VERSION ""

NS_ :

BS_:

BU_: ALLOCATOR ALLOCATEE

BO_ 1823 node_id_discover: 1 ALLOCATOR
 SG_ session_id : 0|8@1+ (1,0) [0|255] ""  ALLOCATEE

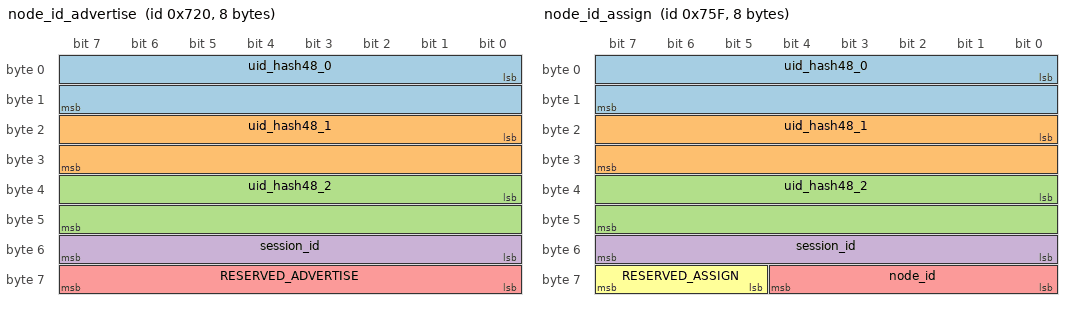
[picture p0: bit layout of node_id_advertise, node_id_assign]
BO_ 1824 node_id_advertise: 8 ALLOCATEE
 SG_ uid_hash48_0 : 0|16@1+ (1,0) [0|65535] "hash48_0"  ALLOCATOR
 SG_ uid_hash48_1 : 16|16@1+ (1,0) [0|65535] "hash48_1"  ALLOCATOR
 SG_ uid_hash48_2 : 32|16@1+ (1,0) [0|65535] "hash48_2"  ALLOCATOR
 SG_ session_id : 48|8@1+ (1,0) [0|255] "session_id"  ALLOCATOR
 SG_ RESERVED_ADVERTISE : 56|8@1+ (1,0) [0|255] ""  ALLOCATOR

BO_ 1887 node_id_assign: 8 ALLOCATOR
 SG_ uid_hash48_0 : 0|16@1+ (1,0) [0|65535] "hash48_0"  ALLOCATEE
 SG_ uid_hash48_1 : 16|16@1+ (1,0) [0|65535] "hash48_1"  ALLOCATEE
 SG_ uid_hash48_2 : 32|16@1+ (1,0) [0|65535] "hash48_2"  ALLOCATEE
 SG_ session_id : 48|8@1+ (1,0) [0|255] "session_id"  ALLOCATEE
 SG_ node_id : 56|5@1+ (1,0) [0|31] "node_id"  ALLOCATEE
 SG_ RESERVED_ASSIGN : 61|3@1+ (1,0) [0|7] ""  ALLOCATEE

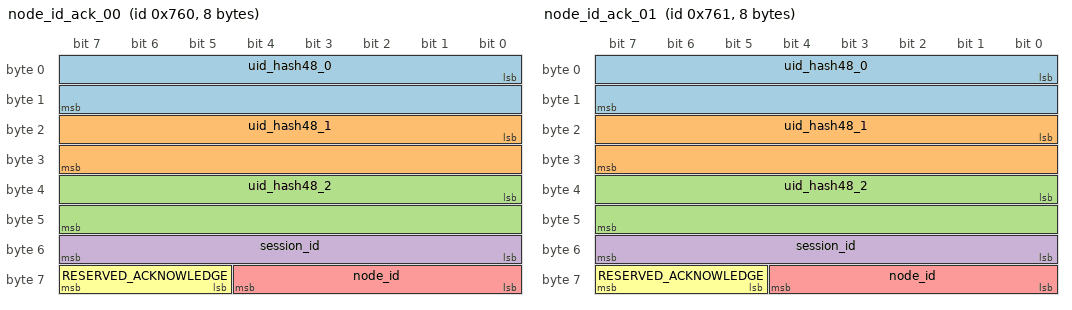
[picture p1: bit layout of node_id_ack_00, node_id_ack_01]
BO_ 1888 node_id_ack_00: 8 ALLOCATEE
 SG_ uid_hash48_0 : 0|16@1+ (1,0) [0|65535] "hash48_0"  ALLOCATOR
 SG_ uid_hash48_1 : 16|16@1+ (1,0) [0|65535] "hash48_1"  ALLOCATOR
 SG_ uid_hash48_2 : 32|16@1+ (1,0) [0|65535] "hash48_2"  ALLOCATOR
 SG_ session_id : 48|8@1+ (1,0) [0|255] "session_id"  ALLOCATOR
 SG_ node_id : 56|5@1+ (1,0) [0|31] "node_id"  ALLOCATOR
 SG_ RESERVED_ACKNOWLEDGE : 61|3@1+ (1,0) [0|7] ""  ALLOCATOR

BO_ 1889 node_id_ack_01: 8 ALLOCATEE
 SG_ uid_hash48_0 : 0|16@1+ (1,0) [0|65535] "hash48_0"  ALLOCATOR
 SG_ uid_hash48_1 : 16|16@1+ (1,0) [0|65535] "hash48_1"  ALLOCATOR
 SG_ uid_hash48_2 : 32|16@1+ (1,0) [0|65535] "hash48_2"  ALLOCATOR
 SG_ session_id : 48|8@1+ (1,0) [0|255] "session_id"  ALLOCATOR
 SG_ node_id : 56|5@1+ (1,0) [0|31] "node_id"  ALLOCATOR
 SG_ RESERVED_ACKNOWLEDGE : 61|3@1+ (1,0) [0|7] ""  ALLOCATOR

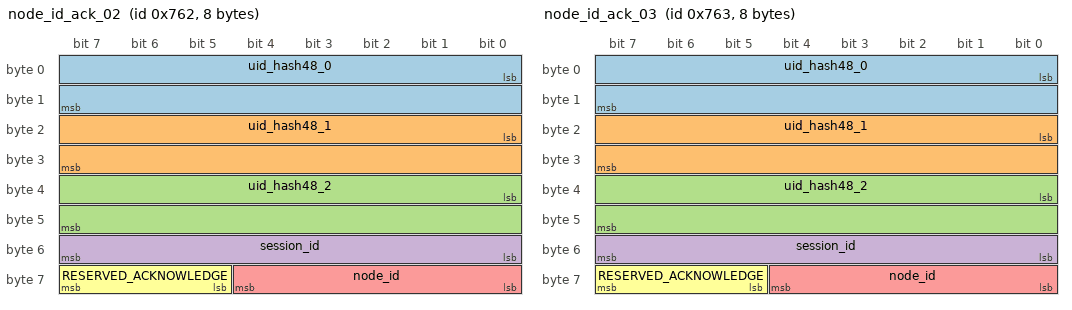
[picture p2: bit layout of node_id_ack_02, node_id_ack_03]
BO_ 1890 node_id_ack_02: 8 ALLOCATEE
 SG_ uid_hash48_0 : 0|16@1+ (1,0) [0|65535] "hash48_0"  ALLOCATOR
 SG_ uid_hash48_1 : 16|16@1+ (1,0) [0|65535] "hash48_1"  ALLOCATOR
 SG_ uid_hash48_2 : 32|16@1+ (1,0) [0|65535] "hash48_2"  ALLOCATOR
 SG_ session_id : 48|8@1+ (1,0) [0|255] "session_id"  ALLOCATOR
 SG_ node_id : 56|5@1+ (1,0) [0|31] "node_id"  ALLOCATOR
 SG_ RESERVED_ACKNOWLEDGE : 61|3@1+ (1,0) [0|7] ""  ALLOCATOR

BO_ 1891 node_id_ack_03: 8 ALLOCATEE
 SG_ uid_hash48_0 : 0|16@1+ (1,0) [0|65535] "hash48_0"  ALLOCATOR
 SG_ uid_hash48_1 : 16|16@1+ (1,0) [0|65535] "hash48_1"  ALLOCATOR
 SG_ uid_hash48_2 : 32|16@1+ (1,0) [0|65535] "hash48_2"  ALLOCATOR
 SG_ session_id : 48|8@1+ (1,0) [0|255] "session_id"  ALLOCATOR
 SG_ node_id : 56|5@1+ (1,0) [0|31] "node_id"  ALLOCATOR
 SG_ RESERVED_ACKNOWLEDGE : 61|3@1+ (1,0) [0|7] ""  ALLOCATOR

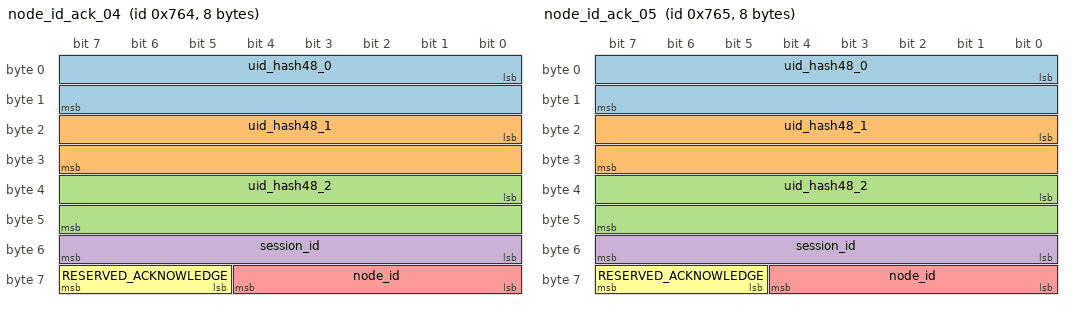
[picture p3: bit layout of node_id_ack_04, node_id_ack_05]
BO_ 1892 node_id_ack_04: 8 ALLOCATEE
 SG_ uid_hash48_0 : 0|16@1+ (1,0) [0|65535] "hash48_0"  ALLOCATOR
 SG_ uid_hash48_1 : 16|16@1+ (1,0) [0|65535] "hash48_1"  ALLOCATOR
 SG_ uid_hash48_2 : 32|16@1+ (1,0) [0|65535] "hash48_2"  ALLOCATOR
 SG_ session_id : 48|8@1+ (1,0) [0|255] "session_id"  ALLOCATOR
 SG_ node_id : 56|5@1+ (1,0) [0|31] "node_id"  ALLOCATOR
 SG_ RESERVED_ACKNOWLEDGE : 61|3@1+ (1,0) [0|7] ""  ALLOCATOR

BO_ 1893 node_id_ack_05: 8 ALLOCATEE
 SG_ uid_hash48_0 : 0|16@1+ (1,0) [0|65535] "hash48_0"  ALLOCATOR
 SG_ uid_hash48_1 : 16|16@1+ (1,0) [0|65535] "hash48_1"  ALLOCATOR
 SG_ uid_hash48_2 : 32|16@1+ (1,0) [0|65535] "hash48_2"  ALLOCATOR
 SG_ session_id : 48|8@1+ (1,0) [0|255] "session_id"  ALLOCATOR
 SG_ node_id : 56|5@1+ (1,0) [0|31] "node_id"  ALLOCATOR
 SG_ RESERVED_ACKNOWLEDGE : 61|3@1+ (1,0) [0|7] ""  ALLOCATOR

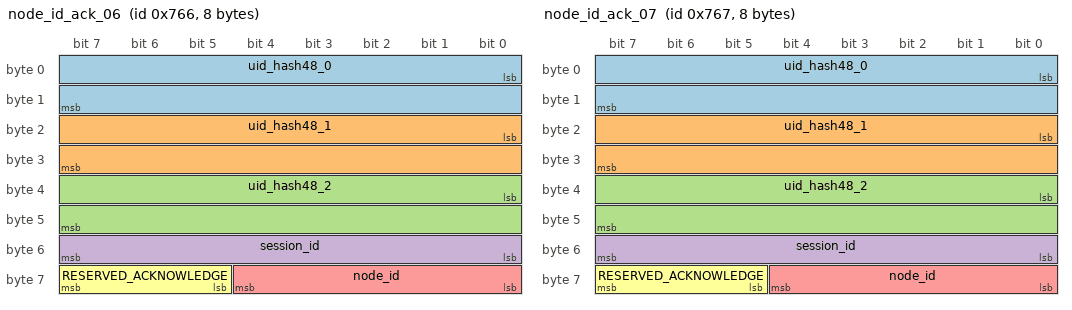
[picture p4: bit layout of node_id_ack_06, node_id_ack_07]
BO_ 1894 node_id_ack_06: 8 ALLOCATEE
 SG_ uid_hash48_0 : 0|16@1+ (1,0) [0|65535] "hash48_0"  ALLOCATOR
 SG_ uid_hash48_1 : 16|16@1+ (1,0) [0|65535] "hash48_1"  ALLOCATOR
 SG_ uid_hash48_2 : 32|16@1+ (1,0) [0|65535] "hash48_2"  ALLOCATOR
 SG_ session_id : 48|8@1+ (1,0) [0|255] "session_id"  ALLOCATOR
 SG_ node_id : 56|5@1+ (1,0) [0|31] "node_id"  ALLOCATOR
 SG_ RESERVED_ACKNOWLEDGE : 61|3@1+ (1,0) [0|7] ""  ALLOCATOR

BO_ 1895 node_id_ack_07: 8 ALLOCATEE
 SG_ uid_hash48_0 : 0|16@1+ (1,0) [0|65535] "hash48_0"  ALLOCATOR
 SG_ uid_hash48_1 : 16|16@1+ (1,0) [0|65535] "hash48_1"  ALLOCATOR
 SG_ uid_hash48_2 : 32|16@1+ (1,0) [0|65535] "hash48_2"  ALLOCATOR
 SG_ session_id : 48|8@1+ (1,0) [0|255] "session_id"  ALLOCATOR
 SG_ node_id : 56|5@1+ (1,0) [0|31] "node_id"  ALLOCATOR
 SG_ RESERVED_ACKNOWLEDGE : 61|3@1+ (1,0) [0|7] ""  ALLOCATOR

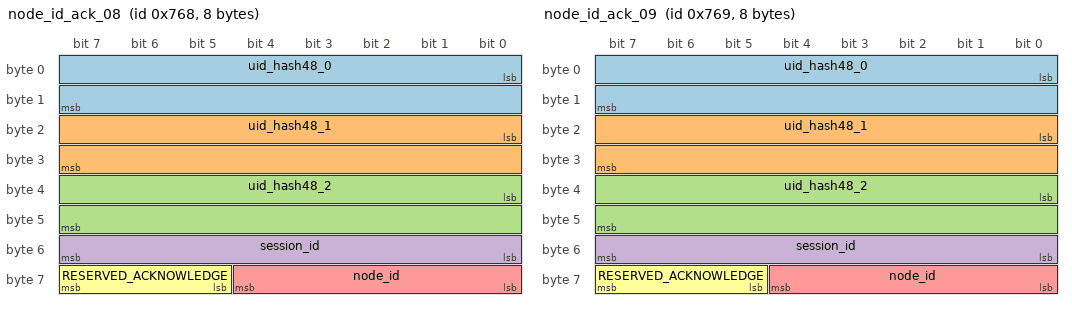
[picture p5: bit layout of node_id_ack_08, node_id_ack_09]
BO_ 1896 node_id_ack_08: 8 ALLOCATEE
 SG_ uid_hash48_0 : 0|16@1+ (1,0) [0|65535] "hash48_0"  ALLOCATOR
 SG_ uid_hash48_1 : 16|16@1+ (1,0) [0|65535] "hash48_1"  ALLOCATOR
 SG_ uid_hash48_2 : 32|16@1+ (1,0) [0|65535] "hash48_2"  ALLOCATOR
 SG_ session_id : 48|8@1+ (1,0) [0|255] "session_id"  ALLOCATOR
 SG_ node_id : 56|5@1+ (1,0) [0|31] "node_id"  ALLOCATOR
 SG_ RESERVED_ACKNOWLEDGE : 61|3@1+ (1,0) [0|7] ""  ALLOCATOR

BO_ 1897 node_id_ack_09: 8 ALLOCATEE
 SG_ uid_hash48_0 : 0|16@1+ (1,0) [0|65535] "hash48_0"  ALLOCATOR
 SG_ uid_hash48_1 : 16|16@1+ (1,0) [0|65535] "hash48_1"  ALLOCATOR
 SG_ uid_hash48_2 : 32|16@1+ (1,0) [0|65535] "hash48_2"  ALLOCATOR
 SG_ session_id : 48|8@1+ (1,0) [0|255] "session_id"  ALLOCATOR
 SG_ node_id : 56|5@1+ (1,0) [0|31] "node_id"  ALLOCATOR
 SG_ RESERVED_ACKNOWLEDGE : 61|3@1+ (1,0) [0|7] ""  ALLOCATOR

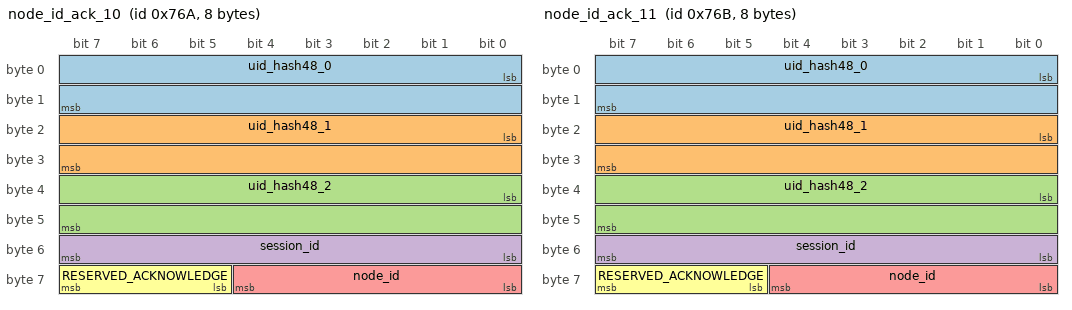
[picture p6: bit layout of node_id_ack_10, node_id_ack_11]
BO_ 1898 node_id_ack_10: 8 ALLOCATEE
 SG_ uid_hash48_0 : 0|16@1+ (1,0) [0|65535] "hash48_0"  ALLOCATOR
 SG_ uid_hash48_1 : 16|16@1+ (1,0) [0|65535] "hash48_1"  ALLOCATOR
 SG_ uid_hash48_2 : 32|16@1+ (1,0) [0|65535] "hash48_2"  ALLOCATOR
 SG_ session_id : 48|8@1+ (1,0) [0|255] "session_id"  ALLOCATOR
 SG_ node_id : 56|5@1+ (1,0) [0|31] "node_id"  ALLOCATOR
 SG_ RESERVED_ACKNOWLEDGE : 61|3@1+ (1,0) [0|7] ""  ALLOCATOR

BO_ 1899 node_id_ack_11: 8 ALLOCATEE
 SG_ uid_hash48_0 : 0|16@1+ (1,0) [0|65535] "hash48_0"  ALLOCATOR
 SG_ uid_hash48_1 : 16|16@1+ (1,0) [0|65535] "hash48_1"  ALLOCATOR
 SG_ uid_hash48_2 : 32|16@1+ (1,0) [0|65535] "hash48_2"  ALLOCATOR
 SG_ session_id : 48|8@1+ (1,0) [0|255] "session_id"  ALLOCATOR
 SG_ node_id : 56|5@1+ (1,0) [0|31] "node_id"  ALLOCATOR
 SG_ RESERVED_ACKNOWLEDGE : 61|3@1+ (1,0) [0|7] ""  ALLOCATOR

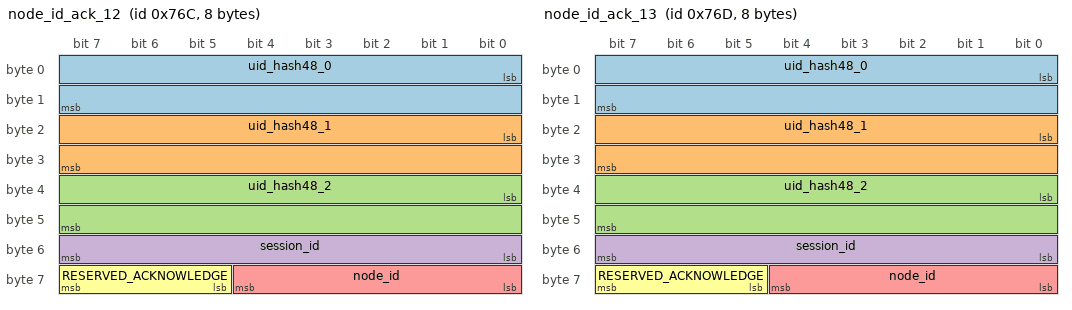
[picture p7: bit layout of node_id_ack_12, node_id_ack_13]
BO_ 1900 node_id_ack_12: 8 ALLOCATEE
 SG_ uid_hash48_0 : 0|16@1+ (1,0) [0|65535] "hash48_0"  ALLOCATOR
 SG_ uid_hash48_1 : 16|16@1+ (1,0) [0|65535] "hash48_1"  ALLOCATOR
 SG_ uid_hash48_2 : 32|16@1+ (1,0) [0|65535] "hash48_2"  ALLOCATOR
 SG_ session_id : 48|8@1+ (1,0) [0|255] "session_id"  ALLOCATOR
 SG_ node_id : 56|5@1+ (1,0) [0|31] "node_id"  ALLOCATOR
 SG_ RESERVED_ACKNOWLEDGE : 61|3@1+ (1,0) [0|7] ""  ALLOCATOR

BO_ 1901 node_id_ack_13: 8 ALLOCATEE
 SG_ uid_hash48_0 : 0|16@1+ (1,0) [0|65535] "hash48_0"  ALLOCATOR
 SG_ uid_hash48_1 : 16|16@1+ (1,0) [0|65535] "hash48_1"  ALLOCATOR
 SG_ uid_hash48_2 : 32|16@1+ (1,0) [0|65535] "hash48_2"  ALLOCATOR
 SG_ session_id : 48|8@1+ (1,0) [0|255] "session_id"  ALLOCATOR
 SG_ node_id : 56|5@1+ (1,0) [0|31] "node_id"  ALLOCATOR
 SG_ RESERVED_ACKNOWLEDGE : 61|3@1+ (1,0) [0|7] ""  ALLOCATOR

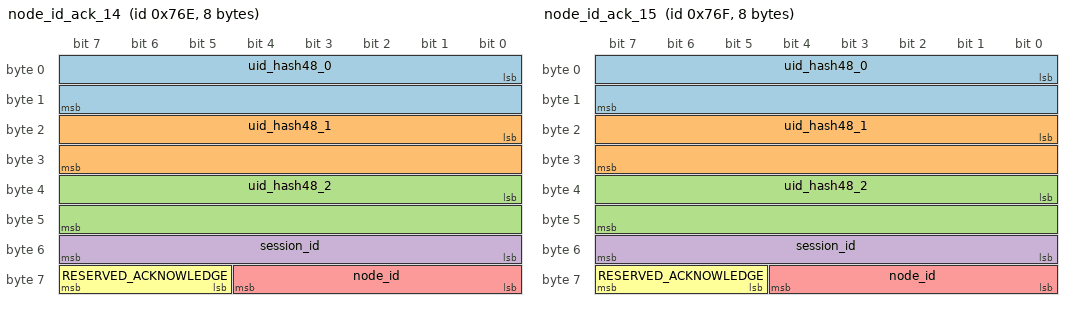
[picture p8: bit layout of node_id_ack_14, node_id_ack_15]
BO_ 1902 node_id_ack_14: 8 ALLOCATEE
 SG_ uid_hash48_0 : 0|16@1+ (1,0) [0|65535] "hash48_0"  ALLOCATOR
 SG_ uid_hash48_1 : 16|16@1+ (1,0) [0|65535] "hash48_1"  ALLOCATOR
 SG_ uid_hash48_2 : 32|16@1+ (1,0) [0|65535] "hash48_2"  ALLOCATOR
 SG_ session_id : 48|8@1+ (1,0) [0|255] "session_id"  ALLOCATOR
 SG_ node_id : 56|5@1+ (1,0) [0|31] "node_id"  ALLOCATOR
 SG_ RESERVED_ACKNOWLEDGE : 61|3@1+ (1,0) [0|7] ""  ALLOCATOR

BO_ 1903 node_id_ack_15: 8 ALLOCATEE
 SG_ uid_hash48_0 : 0|16@1+ (1,0) [0|65535] "hash48_0"  ALLOCATOR
 SG_ uid_hash48_1 : 16|16@1+ (1,0) [0|65535] "hash48_1"  ALLOCATOR
 SG_ uid_hash48_2 : 32|16@1+ (1,0) [0|65535] "hash48_2"  ALLOCATOR
 SG_ session_id : 48|8@1+ (1,0) [0|255] "session_id"  ALLOCATOR
 SG_ node_id : 56|5@1+ (1,0) [0|31] "node_id"  ALLOCATOR
 SG_ RESERVED_ACKNOWLEDGE : 61|3@1+ (1,0) [0|7] ""  ALLOCATOR

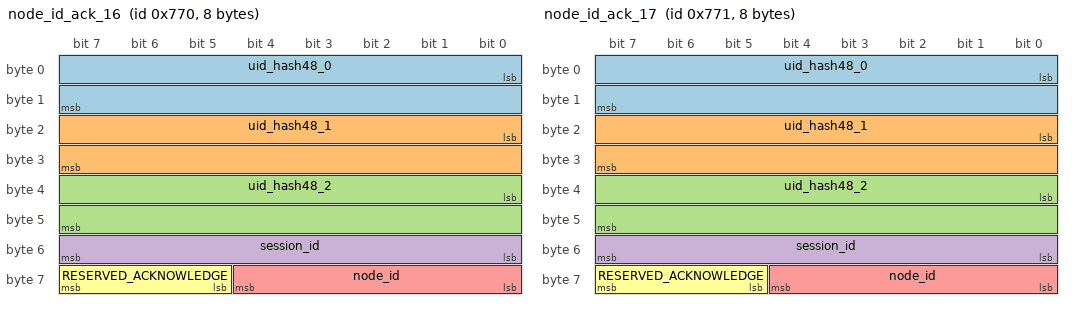
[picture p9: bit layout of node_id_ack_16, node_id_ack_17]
BO_ 1904 node_id_ack_16: 8 ALLOCATEE
 SG_ uid_hash48_0 : 0|16@1+ (1,0) [0|65535] "hash48_0"  ALLOCATOR
 SG_ uid_hash48_1 : 16|16@1+ (1,0) [0|65535] "hash48_1"  ALLOCATOR
 SG_ uid_hash48_2 : 32|16@1+ (1,0) [0|65535] "hash48_2"  ALLOCATOR
 SG_ session_id : 48|8@1+ (1,0) [0|255] "session_id"  ALLOCATOR
 SG_ node_id : 56|5@1+ (1,0) [0|31] "node_id"  ALLOCATOR
 SG_ RESERVED_ACKNOWLEDGE : 61|3@1+ (1,0) [0|7] ""  ALLOCATOR

BO_ 1905 node_id_ack_17: 8 ALLOCATEE
 SG_ uid_hash48_0 : 0|16@1+ (1,0) [0|65535] "hash48_0"  ALLOCATOR
 SG_ uid_hash48_1 : 16|16@1+ (1,0) [0|65535] "hash48_1"  ALLOCATOR
 SG_ uid_hash48_2 : 32|16@1+ (1,0) [0|65535] "hash48_2"  ALLOCATOR
 SG_ session_id : 48|8@1+ (1,0) [0|255] "session_id"  ALLOCATOR
 SG_ node_id : 56|5@1+ (1,0) [0|31] "node_id"  ALLOCATOR
 SG_ RESERVED_ACKNOWLEDGE : 61|3@1+ (1,0) [0|7] ""  ALLOCATOR

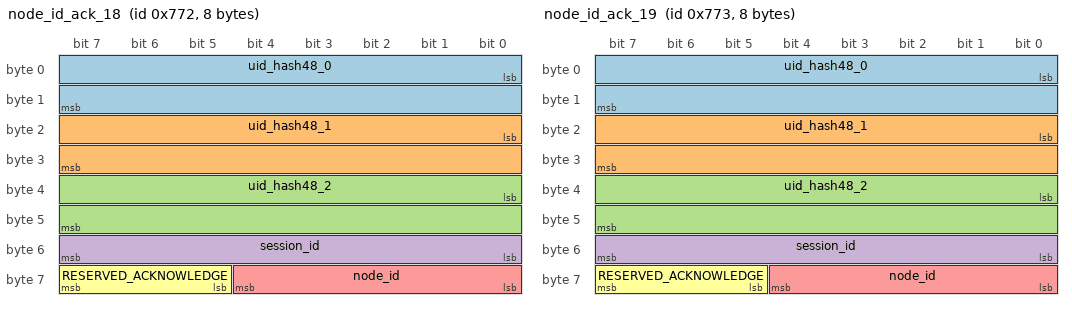
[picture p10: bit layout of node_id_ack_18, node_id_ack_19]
BO_ 1906 node_id_ack_18: 8 ALLOCATEE
 SG_ uid_hash48_0 : 0|16@1+ (1,0) [0|65535] "hash48_0"  ALLOCATOR
 SG_ uid_hash48_1 : 16|16@1+ (1,0) [0|65535] "hash48_1"  ALLOCATOR
 SG_ uid_hash48_2 : 32|16@1+ (1,0) [0|65535] "hash48_2"  ALLOCATOR
 SG_ session_id : 48|8@1+ (1,0) [0|255] "session_id"  ALLOCATOR
 SG_ node_id : 56|5@1+ (1,0) [0|31] "node_id"  ALLOCATOR
 SG_ RESERVED_ACKNOWLEDGE : 61|3@1+ (1,0) [0|7] ""  ALLOCATOR

BO_ 1907 node_id_ack_19: 8 ALLOCATEE
 SG_ uid_hash48_0 : 0|16@1+ (1,0) [0|65535] "hash48_0"  ALLOCATOR
 SG_ uid_hash48_1 : 16|16@1+ (1,0) [0|65535] "hash48_1"  ALLOCATOR
 SG_ uid_hash48_2 : 32|16@1+ (1,0) [0|65535] "hash48_2"  ALLOCATOR
 SG_ session_id : 48|8@1+ (1,0) [0|255] "session_id"  ALLOCATOR
 SG_ node_id : 56|5@1+ (1,0) [0|31] "node_id"  ALLOCATOR
 SG_ RESERVED_ACKNOWLEDGE : 61|3@1+ (1,0) [0|7] ""  ALLOCATOR

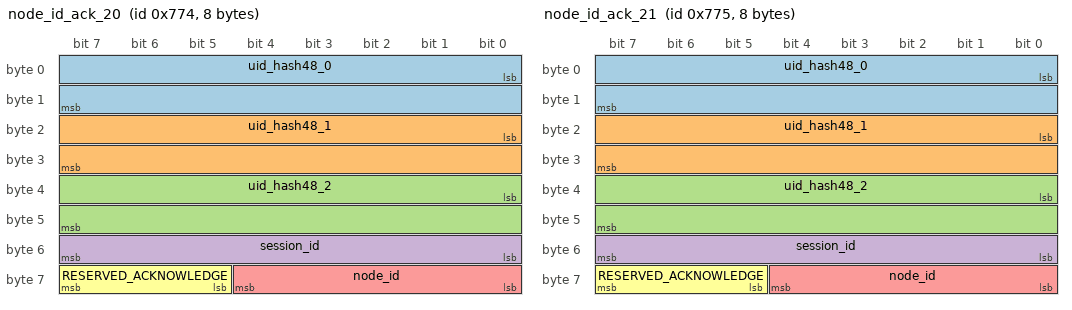
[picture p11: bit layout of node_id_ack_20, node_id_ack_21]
BO_ 1908 node_id_ack_20: 8 ALLOCATEE
 SG_ uid_hash48_0 : 0|16@1+ (1,0) [0|65535] "hash48_0"  ALLOCATOR
 SG_ uid_hash48_1 : 16|16@1+ (1,0) [0|65535] "hash48_1"  ALLOCATOR
 SG_ uid_hash48_2 : 32|16@1+ (1,0) [0|65535] "hash48_2"  ALLOCATOR
 SG_ session_id : 48|8@1+ (1,0) [0|255] "session_id"  ALLOCATOR
 SG_ node_id : 56|5@1+ (1,0) [0|31] "node_id"  ALLOCATOR
 SG_ RESERVED_ACKNOWLEDGE : 61|3@1+ (1,0) [0|7] ""  ALLOCATOR

BO_ 1909 node_id_ack_21: 8 ALLOCATEE
 SG_ uid_hash48_0 : 0|16@1+ (1,0) [0|65535] "hash48_0"  ALLOCATOR
 SG_ uid_hash48_1 : 16|16@1+ (1,0) [0|65535] "hash48_1"  ALLOCATOR
 SG_ uid_hash48_2 : 32|16@1+ (1,0) [0|65535] "hash48_2"  ALLOCATOR
 SG_ session_id : 48|8@1+ (1,0) [0|255] "session_id"  ALLOCATOR
 SG_ node_id : 56|5@1+ (1,0) [0|31] "node_id"  ALLOCATOR
 SG_ RESERVED_ACKNOWLEDGE : 61|3@1+ (1,0) [0|7] ""  ALLOCATOR

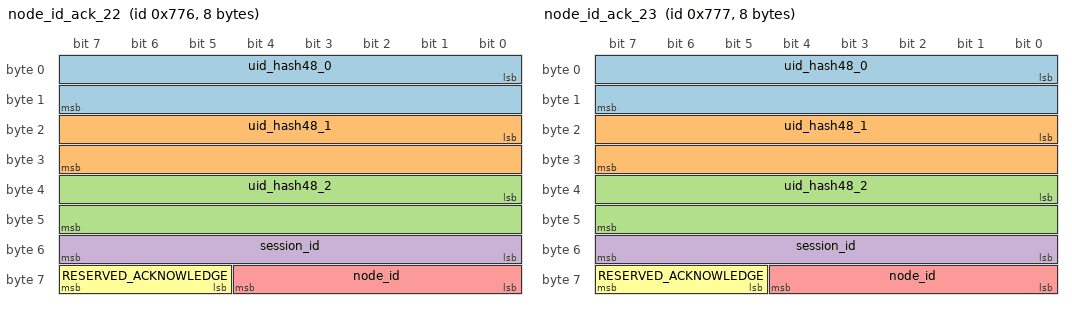
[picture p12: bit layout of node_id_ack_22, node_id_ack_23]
BO_ 1910 node_id_ack_22: 8 ALLOCATEE
 SG_ uid_hash48_0 : 0|16@1+ (1,0) [0|65535] "hash48_0"  ALLOCATOR
 SG_ uid_hash48_1 : 16|16@1+ (1,0) [0|65535] "hash48_1"  ALLOCATOR
 SG_ uid_hash48_2 : 32|16@1+ (1,0) [0|65535] "hash48_2"  ALLOCATOR
 SG_ session_id : 48|8@1+ (1,0) [0|255] "session_id"  ALLOCATOR
 SG_ node_id : 56|5@1+ (1,0) [0|31] "node_id"  ALLOCATOR
 SG_ RESERVED_ACKNOWLEDGE : 61|3@1+ (1,0) [0|7] ""  ALLOCATOR

BO_ 1911 node_id_ack_23: 8 ALLOCATEE
 SG_ uid_hash48_0 : 0|16@1+ (1,0) [0|65535] "hash48_0"  ALLOCATOR
 SG_ uid_hash48_1 : 16|16@1+ (1,0) [0|65535] "hash48_1"  ALLOCATOR
 SG_ uid_hash48_2 : 32|16@1+ (1,0) [0|65535] "hash48_2"  ALLOCATOR
 SG_ session_id : 48|8@1+ (1,0) [0|255] "session_id"  ALLOCATOR
 SG_ node_id : 56|5@1+ (1,0) [0|31] "node_id"  ALLOCATOR
 SG_ RESERVED_ACKNOWLEDGE : 61|3@1+ (1,0) [0|7] ""  ALLOCATOR

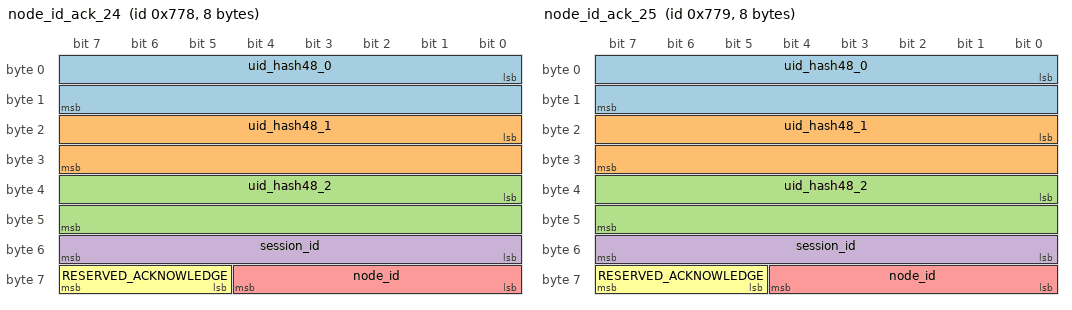
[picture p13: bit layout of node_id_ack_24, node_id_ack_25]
BO_ 1912 node_id_ack_24: 8 ALLOCATEE
 SG_ uid_hash48_0 : 0|16@1+ (1,0) [0|65535] "hash48_0"  ALLOCATOR
 SG_ uid_hash48_1 : 16|16@1+ (1,0) [0|65535] "hash48_1"  ALLOCATOR
 SG_ uid_hash48_2 : 32|16@1+ (1,0) [0|65535] "hash48_2"  ALLOCATOR
 SG_ session_id : 48|8@1+ (1,0) [0|255] "session_id"  ALLOCATOR
 SG_ node_id : 56|5@1+ (1,0) [0|31] "node_id"  ALLOCATOR
 SG_ RESERVED_ACKNOWLEDGE : 61|3@1+ (1,0) [0|7] ""  ALLOCATOR

BO_ 1913 node_id_ack_25: 8 ALLOCATEE
 SG_ uid_hash48_0 : 0|16@1+ (1,0) [0|65535] "hash48_0"  ALLOCATOR
 SG_ uid_hash48_1 : 16|16@1+ (1,0) [0|65535] "hash48_1"  ALLOCATOR
 SG_ uid_hash48_2 : 32|16@1+ (1,0) [0|65535] "hash48_2"  ALLOCATOR
 SG_ session_id : 48|8@1+ (1,0) [0|255] "session_id"  ALLOCATOR
 SG_ node_id : 56|5@1+ (1,0) [0|31] "node_id"  ALLOCATOR
 SG_ RESERVED_ACKNOWLEDGE : 61|3@1+ (1,0) [0|7] ""  ALLOCATOR

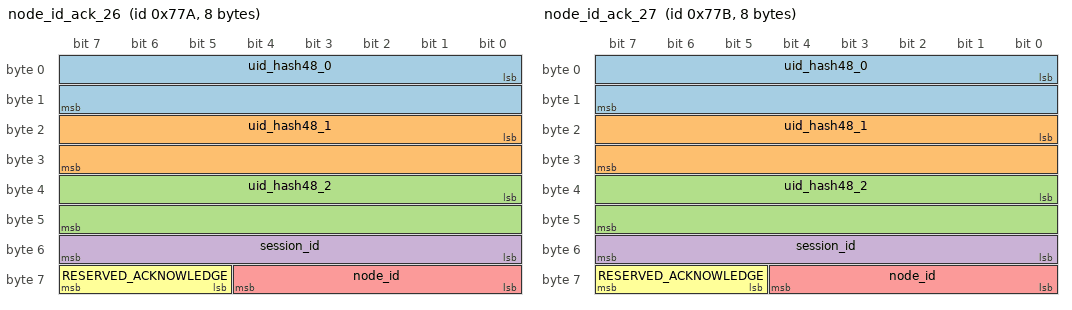
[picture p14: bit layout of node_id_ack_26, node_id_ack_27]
BO_ 1914 node_id_ack_26: 8 ALLOCATEE
 SG_ uid_hash48_0 : 0|16@1+ (1,0) [0|65535] "hash48_0"  ALLOCATOR
 SG_ uid_hash48_1 : 16|16@1+ (1,0) [0|65535] "hash48_1"  ALLOCATOR
 SG_ uid_hash48_2 : 32|16@1+ (1,0) [0|65535] "hash48_2"  ALLOCATOR
 SG_ session_id : 48|8@1+ (1,0) [0|255] "session_id"  ALLOCATOR
 SG_ node_id : 56|5@1+ (1,0) [0|31] "node_id"  ALLOCATOR
 SG_ RESERVED_ACKNOWLEDGE : 61|3@1+ (1,0) [0|7] ""  ALLOCATOR

BO_ 1915 node_id_ack_27: 8 ALLOCATEE
 SG_ uid_hash48_0 : 0|16@1+ (1,0) [0|65535] "hash48_0"  ALLOCATOR
 SG_ uid_hash48_1 : 16|16@1+ (1,0) [0|65535] "hash48_1"  ALLOCATOR
 SG_ uid_hash48_2 : 32|16@1+ (1,0) [0|65535] "hash48_2"  ALLOCATOR
 SG_ session_id : 48|8@1+ (1,0) [0|255] "session_id"  ALLOCATOR
 SG_ node_id : 56|5@1+ (1,0) [0|31] "node_id"  ALLOCATOR
 SG_ RESERVED_ACKNOWLEDGE : 61|3@1+ (1,0) [0|7] ""  ALLOCATOR

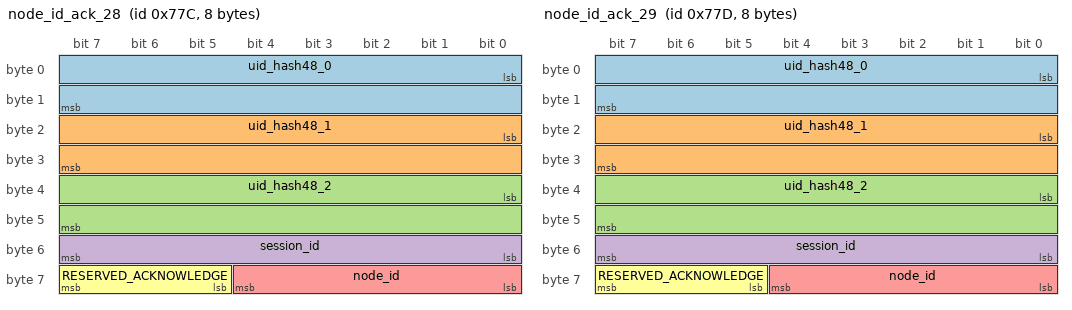
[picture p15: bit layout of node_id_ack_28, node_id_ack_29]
BO_ 1916 node_id_ack_28: 8 ALLOCATEE
 SG_ uid_hash48_0 : 0|16@1+ (1,0) [0|65535] "hash48_0"  ALLOCATOR
 SG_ uid_hash48_1 : 16|16@1+ (1,0) [0|65535] "hash48_1"  ALLOCATOR
 SG_ uid_hash48_2 : 32|16@1+ (1,0) [0|65535] "hash48_2"  ALLOCATOR
 SG_ session_id : 48|8@1+ (1,0) [0|255] "session_id"  ALLOCATOR
 SG_ node_id : 56|5@1+ (1,0) [0|31] "node_id"  ALLOCATOR
 SG_ RESERVED_ACKNOWLEDGE : 61|3@1+ (1,0) [0|7] ""  ALLOCATOR

BO_ 1917 node_id_ack_29: 8 ALLOCATEE
 SG_ uid_hash48_0 : 0|16@1+ (1,0) [0|65535] "hash48_0"  ALLOCATOR
 SG_ uid_hash48_1 : 16|16@1+ (1,0) [0|65535] "hash48_1"  ALLOCATOR
 SG_ uid_hash48_2 : 32|16@1+ (1,0) [0|65535] "hash48_2"  ALLOCATOR
 SG_ session_id : 48|8@1+ (1,0) [0|255] "session_id"  ALLOCATOR
 SG_ node_id : 56|5@1+ (1,0) [0|31] "node_id"  ALLOCATOR
 SG_ RESERVED_ACKNOWLEDGE : 61|3@1+ (1,0) [0|7] ""  ALLOCATOR

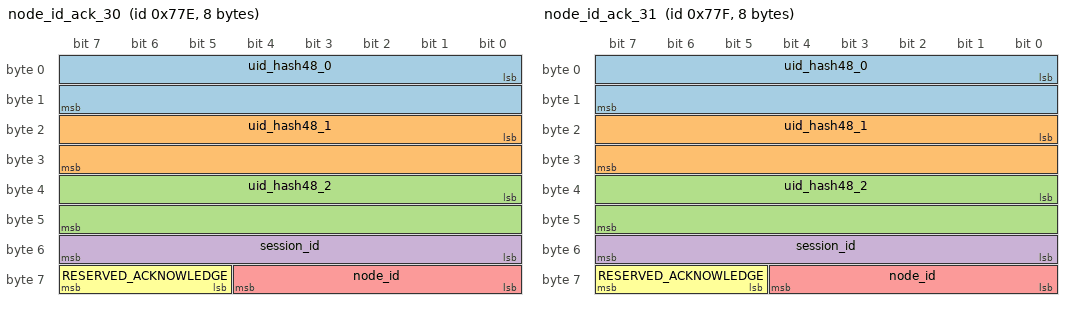
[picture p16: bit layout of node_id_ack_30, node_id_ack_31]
BO_ 1918 node_id_ack_30: 8 ALLOCATEE
 SG_ uid_hash48_0 : 0|16@1+ (1,0) [0|65535] "hash48_0"  ALLOCATOR
 SG_ uid_hash48_1 : 16|16@1+ (1,0) [0|65535] "hash48_1"  ALLOCATOR
 SG_ uid_hash48_2 : 32|16@1+ (1,0) [0|65535] "hash48_2"  ALLOCATOR
 SG_ session_id : 48|8@1+ (1,0) [0|255] "session_id"  ALLOCATOR
 SG_ node_id : 56|5@1+ (1,0) [0|31] "node_id"  ALLOCATOR
 SG_ RESERVED_ACKNOWLEDGE : 61|3@1+ (1,0) [0|7] ""  ALLOCATOR

BO_ 1919 node_id_ack_31: 8 ALLOCATEE
 SG_ uid_hash48_0 : 0|16@1+ (1,0) [0|65535] "hash48_0"  ALLOCATOR
 SG_ uid_hash48_1 : 16|16@1+ (1,0) [0|65535] "hash48_1"  ALLOCATOR
 SG_ uid_hash48_2 : 32|16@1+ (1,0) [0|65535] "hash48_2"  ALLOCATOR
 SG_ session_id : 48|8@1+ (1,0) [0|255] "session_id"  ALLOCATOR
 SG_ node_id : 56|5@1+ (1,0) [0|31] "node_id"  ALLOCATOR
 SG_ RESERVED_ACKNOWLEDGE : 61|3@1+ (1,0) [0|7] ""  ALLOCATOR

BA_DEF_  "BusType" STRING ;
BA_DEF_DEF_  "BusType" "CAN";
